VERSION "HIPBNYYYYYYYYYYYYYYYYYYYYYYYYYYYYYYYYYYYYY/4/%%%/4/'%**4YYY///"

NS_ :

BS_:

BU_:

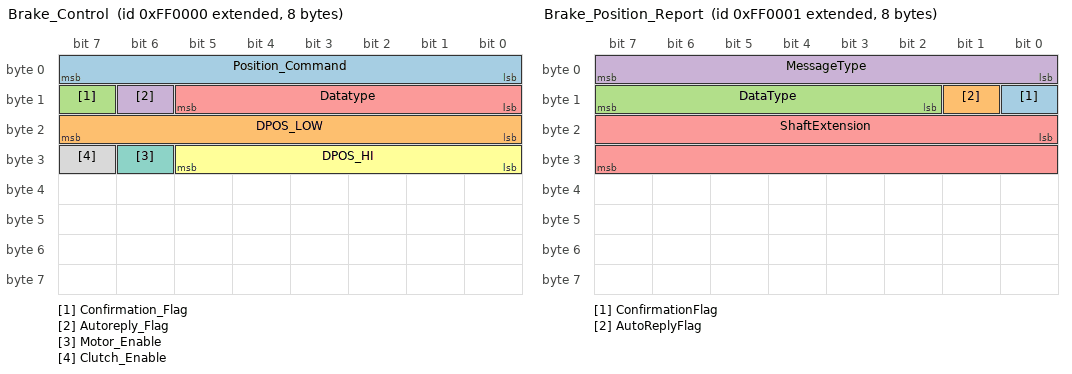
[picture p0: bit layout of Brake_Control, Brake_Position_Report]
BO_ 2164195328 Brake_Control: 8 Vector__XXX
 SG_ Position_Command : 0|8@1+ (1,0) [0|0] "" Vector__XXX
 SG_ DPOS_LOW : 16|8@1+ (1,0) [0|0] "" Vector__XXX
 SG_ Confirmation_Flag : 15|1@1+ (1,0) [0|0] "" Vector__XXX
 SG_ Autoreply_Flag : 14|1@1+ (1,0) [0|0] "" Vector__XXX
 SG_ Datatype : 8|6@1+ (1,0) [0|0] "" Vector__XXX
 SG_ DPOS_HI : 24|6@1+ (1,0) [0|0] "" Vector__XXX
 SG_ Motor_Enable : 30|1@1+ (1,0) [0|0] "" Vector__XXX
 SG_ Clutch_Enable : 31|1@1+ (1,0) [0|0] "" Vector__XXX

BO_ 2164195329 Brake_Position_Report: 8 Vector__XXX
 SG_ ConfirmationFlag : 8|1@1+ (1,0) [0|0] "" Vector__XXX
 SG_ AutoReplyFlag : 9|1@1+ (1,0) [0|0] "" Vector__XXX
 SG_ DataType : 10|6@1+ (1,0) [0|0] "" Vector__XXX
 SG_ MessageType : 0|8@1+ (1,0) [0|0] "" Vector__XXX
 SG_ ShaftExtension : 16|16@1+ (1,0) [0|0] "" Vector__XXX

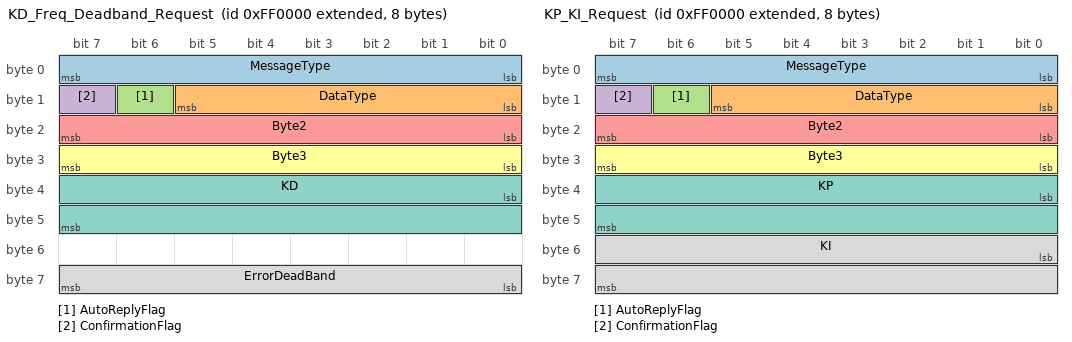
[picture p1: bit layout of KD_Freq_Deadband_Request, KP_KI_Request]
BO_ 2164195328 KD_Freq_Deadband_Request: 8 Vector__XXX
 SG_ MessageType : 0|8@1+ (1,0) [0|0] "" Vector__XXX
 SG_ DataType : 8|6@1+ (1,0) [0|0] "" Vector__XXX
 SG_ AutoReplyFlag : 14|1@1+ (1,0) [0|0] "" Vector__XXX
 SG_ ConfirmationFlag : 15|1@1+ (1,0) [0|0] "" Vector__XXX
 SG_ Byte2 : 16|8@1+ (1,0) [0|0] "" Vector__XXX
 SG_ Byte3 : 24|8@1+ (1,0) [0|0] "" Vector__XXX
 SG_ KD : 32|16@1+ (1,0) [0|0] "" Vector__XXX
 SG_ ErrorDeadBand : 56|8@1+ (1,0) [0|0] "" Vector__XXX

BO_ 2164195328 KP_KI_Request: 8 Vector__XXX
 SG_ MessageType : 0|8@1+ (1,0) [0|0] "" Vector__XXX
 SG_ DataType : 8|6@1+ (1,0) [0|0] "" Vector__XXX
 SG_ AutoReplyFlag : 14|1@1+ (1,0) [0|0] "" Vector__XXX
 SG_ ConfirmationFlag : 15|1@1+ (1,0) [0|0] "" Vector__XXX
 SG_ Byte2 : 16|8@1+ (1,0) [0|0] "" Vector__XXX
 SG_ Byte3 : 24|8@1+ (1,0) [0|0] "" Vector__XXX
 SG_ KP : 32|16@1+ (1,0) [0|0] "" Vector__XXX
 SG_ KI : 48|16@1+ (1,0) [0|0] "" Vector__XXX

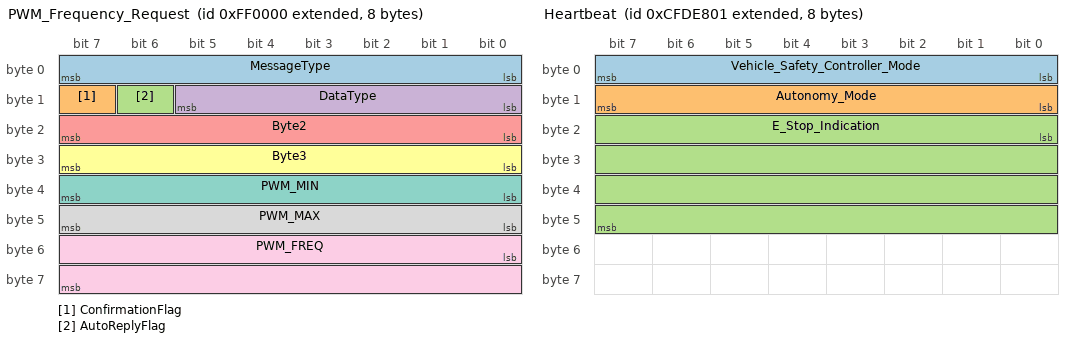
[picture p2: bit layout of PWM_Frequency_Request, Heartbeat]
BO_ 2164195328 PWM_Frequency_Request: 8 Vector__XXX
 SG_ MessageType : 0|8@1+ (1,0) [0|0] "" Vector__XXX
 SG_ ConfirmationFlag : 15|1@1+ (1,0) [0|0] "" Vector__XXX
 SG_ AutoReplyFlag : 14|1@1+ (1,0) [0|0] "" Vector__XXX
 SG_ DataType : 8|6@1+ (1,0) [0|0] "" Vector__XXX
 SG_ Byte2 : 16|8@1+ (1,0) [0|0] "" Vector__XXX
 SG_ Byte3 : 24|8@1+ (1,0) [0|0] "" Vector__XXX
 SG_ PWM_MIN : 32|8@1+ (1,0) [0|0] "" Vector__XXX
 SG_ PWM_MAX : 40|8@1+ (1,0) [0|0] "" Vector__XXX
 SG_ PWM_FREQ : 48|16@1+ (1,0) [0|0] "" Vector__XXX

BO_ 2365450241 Heartbeat: 8 Vector__XXX
 SG_ Vehicle_Safety_Controller_Mode : 0|8@1+ (1,0) [0|0] "" Vector__XXX
 SG_ Autonomy_Mode : 8|8@1+ (1,0) [0|0] "" Vector__XXX
 SG_ E_Stop_Indication : 16|32@1+ (1,0) [0|0] "" Vector__XXX

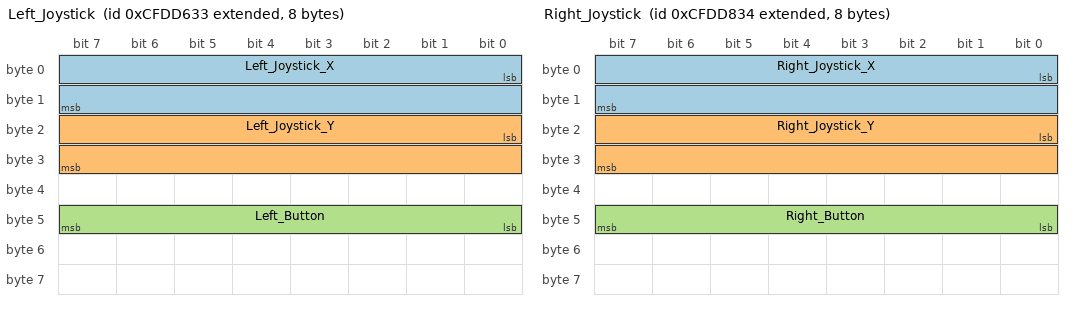
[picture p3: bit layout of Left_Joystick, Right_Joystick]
BO_ 2365445683 Left_Joystick: 8 Vector__XXX
 SG_ Left_Joystick_X : 0|16@1+ (1,0) [0|0] "" Vector__XXX
 SG_ Left_Joystick_Y : 16|16@1+ (1,0) [0|0] "" Vector__XXX
 SG_ Left_Button : 40|8@1+ (1,0) [0|0] "" Vector__XXX

BO_ 2365446196 Right_Joystick: 8 Vector__XXX
 SG_ Right_Joystick_X : 0|16@1+ (1,0) [0|0] "" Vector__XXX
 SG_ Right_Joystick_Y : 16|16@1+ (1,0) [0|0] "" Vector__XXX
 SG_ Right_Button : 40|8@1+ (1,0) [0|0] "" Vector__XXX

BO_ 1420 Front_Right_Wheel_Encoder: 8 Vector__XXX
 SG_ Velocity : 32|16@1- (1,0) [-3200|3200] "" Vector__XXX

BO_ 1440 Front_Left_Wheel_Encoder: 8 Vector__XXX
 SG_ Velocity : 32|16@1- (1,0) [-3200|3200] "" Vector__XXX

BO_ 1419 Rear_Axle_Wheel_Encoder: 8 Vector__XXX
 SG_ Velocity : 32|16@1- (1,0) [-3200|3200] "" Vector__XXX

CM_ SG_ 2164195328 Byte2 "Must be set to 0.";
CM_ SG_ 2164195328 Byte3 "Must be set to 0.";
VAL_ 2164195328 Byte2 0 "Default" ;
VAL_ 2164195328 Byte3 1 "Default" 0 "Default" ;
